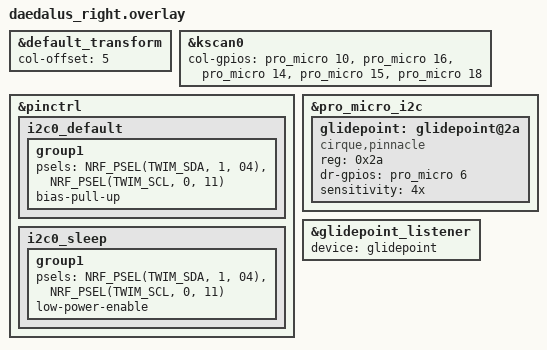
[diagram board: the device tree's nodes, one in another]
#include "daedalus.dtsi"

&default_transform { 
    col-offset = <5>;
};

&kscan0 {
    col-gpios
        = <&pro_micro 10 GPIO_ACTIVE_HIGH> // INNER
        , <&pro_micro 16 GPIO_ACTIVE_HIGH> // INDEX
        , <&pro_micro 14 GPIO_ACTIVE_HIGH> // MIDDLE
        , <&pro_micro 15 GPIO_ACTIVE_HIGH> // RING
        , <&pro_micro 18 GPIO_ACTIVE_HIGH> // PINKY
        ;
};

&pinctrl {
    i2c0_default {
        group1 {
            psels = <NRF_PSEL(TWIM_SDA, 1, 04)>,
                <NRF_PSEL(TWIM_SCL, 0, 11)>;
            bias-pull-up;
        };
    };
    i2c0_sleep: i2c0_sleep {
        group1 {
            psels = <NRF_PSEL(TWIM_SDA, 1, 04)>,
                <NRF_PSEL(TWIM_SCL, 0, 11)>;
            low-power-enable;
        };
    };
};

&pro_micro_i2c {
    status = "okay";
    glidepoint: glidepoint@2a {
        compatible = "cirque,pinnacle";
        status = "okay";
        reg = <0x2a>;
        // Note that this is only applicable in v1.1 or above
        dr-gpios = <&pro_micro 6 (GPIO_ACTIVE_HIGH)>;
        sensitivity = "4x";
    };
};

&glidepoint_listener {
    status = "okay";
    device = <&glidepoint>;
};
